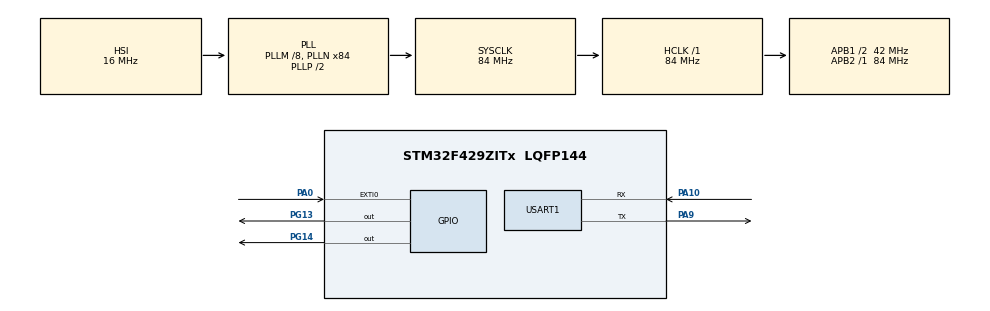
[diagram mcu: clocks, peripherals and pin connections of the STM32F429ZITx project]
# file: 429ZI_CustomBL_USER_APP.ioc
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Mcu.Family=STM32F4
Mcu.Name=STM32F429ZITx
Mcu.Package=LQFP144
NVIC.EXTI0_IRQn=true\:0\:0\:false\:false\:true\:true\:true
NVIC.PriorityGroup=NVIC_PRIORITYGROUP_4
PA0/WKUP.GPIO_ModeDefaultEXTI=GPIO_MODE_IT_RISING
PA0/WKUP.Signal=GPXTI0
PA10.Mode=Asynchronous
PA10.Signal=USART1_RX
PA9.Mode=Asynchronous
PA9.Signal=USART1_TX
PG13.Signal=GPIO_Output
PG14.Signal=GPIO_Output
ProjectManager.HeapSize=0x200
ProjectManager.StackSize=0x400
ProjectManager.TargetToolchain=MDK-ARM V5.27
RCC.48MHZClocksFreq_Value=42000000
RCC.AHBFreq_Value=84000000
RCC.APB1CLKDivider=RCC_HCLK_DIV2
RCC.APB1Freq_Value=42000000
RCC.APB1TimFreq_Value=84000000
RCC.APB2Freq_Value=84000000
RCC.APB2TimFreq_Value=84000000
RCC.CortexFreq_Value=84000000
RCC.HCLKFreq_Value=84000000
RCC.HSE_VALUE=25000000
RCC.HSI_VALUE=16000000
RCC.LSE_VALUE=32768
RCC.PLLM=8
RCC.PLLN=84
RCC.SYSCLKFreq_VALUE=84000000
RCC.SYSCLKSource=RCC_SYSCLKSOURCE_PLLCLK
RCC.VCOOutputFreq_Value=168000000
USART1.VirtualMode=VM_ASYNC
board=custom

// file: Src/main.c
/* USER CODE BEGIN Header */
/**
  ******************************************************************************
  * @file           : main.c
  * @brief          : Main program body
  ******************************************************************************
  * @attention
  *
  * <h2><center>&copy; Copyright (c) 2020 STMicroelectronics.
  * All rights reserved.</center></h2>
  *
  * This software component is licensed by ST under BSD 3-Clause license,
  * the "License"; You may not use this file except in compliance with the
  * License. You may obtain a copy of the License at:
  *                        opensource.org/licenses/BSD-3-Clause
  *
  ******************************************************************************
  */
/* USER CODE END Header */

#include "main.h"
#include "usart.h"
#include "gpio.h"

/* USER CODE BEGIN Includes */
#include "string.h"
/* USER CODE END Includes */

void SystemClock_Config(void);
/* USER CODE BEGIN PFP */
uint8_t msg[] = "Hello Make BootLoader\r\n";
volatile uint8_t flag;
/* USER CODE END PFP */

/* USER CODE BEGIN 0 */
void HAL_GPIO_EXTI_Callback(uint16_t GPIO_Pin)
{
  /* Prevent unused argument(s) compilation warning */
	flag = !flag;
  HAL_GPIO_WritePin(GPIOG, GPIO_PIN_13 | GPIO_PIN_14, flag);
  /* NOTE: This function Should not be modified, when the callback is needed,
           the HAL_GPIO_EXTI_Callback could be implemented in the user file
   */
}
/* USER CODE END 0 */

int main(void)
{

  /* MCU Configuration--------------------------------------------------------*/

  /* Reset of all peripherals, Initializes the Flash interface and the Systick. */
  HAL_Init();

  /* Configure the system clock */
  SystemClock_Config();

  /* Initialize all configured peripherals */
  MX_GPIO_Init();
  MX_USART1_UART_Init();
  /* USER CODE BEGIN 2 */
	flag = 0;
  /* USER CODE END 2 */

  /* Infinite loop */
  while (1)
  {

    /* USER CODE BEGIN 3 */
		uint32_t current_tick = HAL_GetTick();
		HAL_UART_Transmit(&huart1, (uint8_t*)msg, strlen((const char *)msg), HAL_MAX_DELAY);
		while(HAL_GetTick() <= current_tick + 500);
  }
  /* USER CODE END 3 */
}

void SystemClock_Config(void)
{
  RCC_OscInitTypeDef RCC_OscInitStruct = {0};
  RCC_ClkInitTypeDef RCC_ClkInitStruct = {0};

  /** Configure the main internal regulator output voltage
  */
  __HAL_RCC_PWR_CLK_ENABLE();
  __HAL_PWR_VOLTAGESCALING_CONFIG(PWR_REGULATOR_VOLTAGE_SCALE3);
  /** Initializes the CPU, AHB and APB busses clocks
  */
  RCC_OscInitStruct.OscillatorType = RCC_OSCILLATORTYPE_HSI;
  RCC_OscInitStruct.HSIState = RCC_HSI_ON;
  RCC_OscInitStruct.HSICalibrationValue = RCC_HSICALIBRATION_DEFAULT;
  RCC_OscInitStruct.PLL.PLLState = RCC_PLL_ON;
  RCC_OscInitStruct.PLL.PLLSource = RCC_PLLSOURCE_HSI;
  RCC_OscInitStruct.PLL.PLLM = 8;
  RCC_OscInitStruct.PLL.PLLN = 84;
  RCC_OscInitStruct.PLL.PLLP = RCC_PLLP_DIV2;
  RCC_OscInitStruct.PLL.PLLQ = 4;
  if (HAL_RCC_OscConfig(&RCC_OscInitStruct) != HAL_OK)
  {
    Error_Handler();
  }
  /** Initializes the CPU, AHB and APB busses clocks
  */
  RCC_ClkInitStruct.ClockType = RCC_CLOCKTYPE_HCLK|RCC_CLOCKTYPE_SYSCLK
                              |RCC_CLOCKTYPE_PCLK1|RCC_CLOCKTYPE_PCLK2;
  RCC_ClkInitStruct.SYSCLKSource = RCC_SYSCLKSOURCE_PLLCLK;
  RCC_ClkInitStruct.AHBCLKDivider = RCC_SYSCLK_DIV1;
  RCC_ClkInitStruct.APB1CLKDivider = RCC_HCLK_DIV2;
  RCC_ClkInitStruct.APB2CLKDivider = RCC_HCLK_DIV1;

  if (HAL_RCC_ClockConfig(&RCC_ClkInitStruct, FLASH_LATENCY_2) != HAL_OK)
  {
    Error_Handler();
  }
}

void Error_Handler(void)
{
}

/************************ (C) COPYRIGHT STMicroelectronics *****END OF FILE****/
